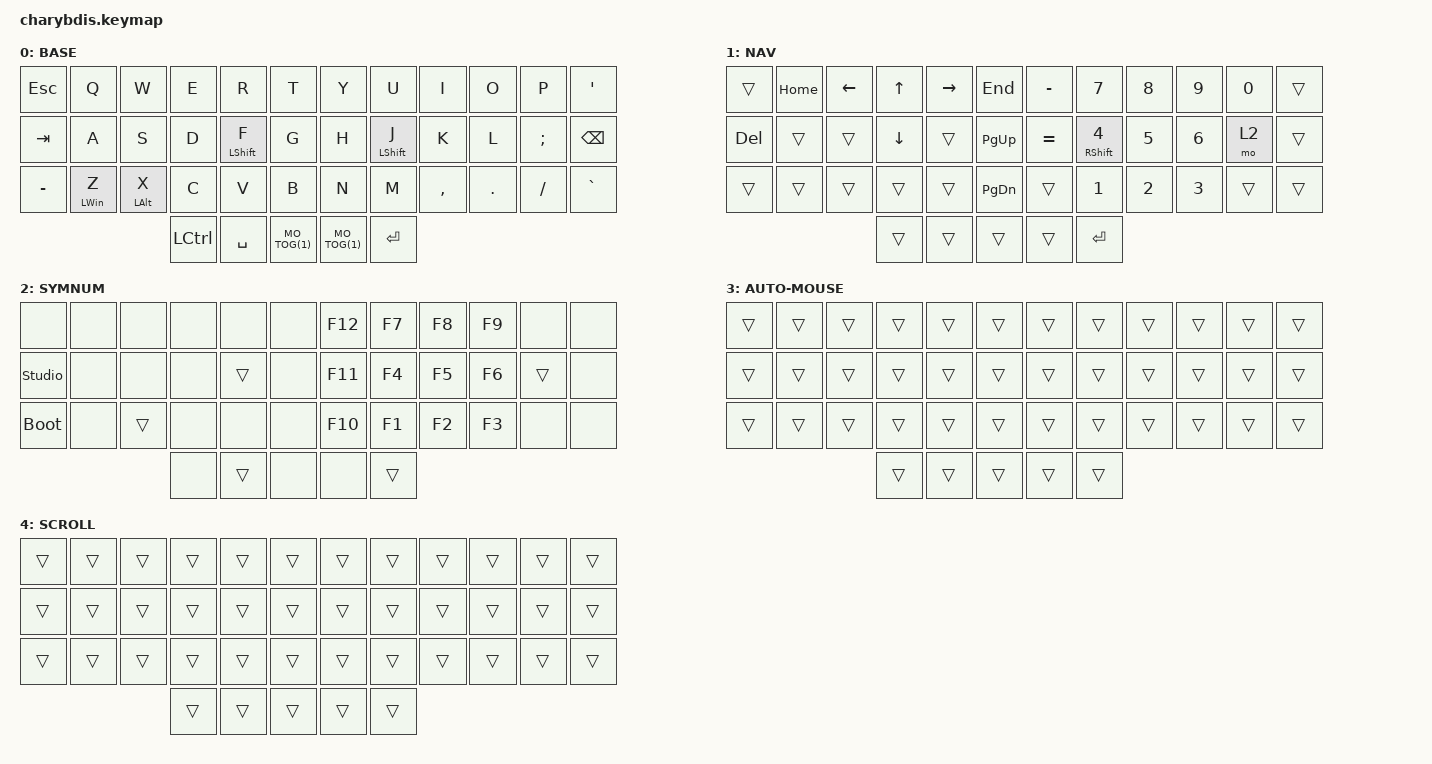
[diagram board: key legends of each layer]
#include <dt-bindings/zmk/mouse.h>
#include <input/processors.dtsi>
#include <dt-bindings/zmk/input_transform.h>
#include <behaviors.dtsi>
#include <dt-bindings/zmk/keys.h>
#include <dt-bindings/zmk/pointing.h>

#define U_TAPPING_TERM 200

#define MO_TOG(layer) &mo_tog layer layer   // Macro to apply momentary-layer-on-hold/toggle-layer-on-tap to a specific layer

/ {
    trackball_listener {
        compatible = "zmk,input-listener";
        device = <&trackball>;
        input-processors = <&zip_xy_scaler 1 2>, <&zip_temp_layer 3 400>;

        // Switch to auto-mouse temp layer, decrease sensitivity

        scroll {
            layers = <4>; // SCROLL
            input-processors =
                <&zip_xy_scaler 1 4>,
                <&zip_xy_to_scroll_mapper>,
                <&zip_scroll_transform (INPUT_TRANSFORM_Y_INVERT)>;
        };
    };

    combos {
        compatible = "zmk,combos";

        LeftClickRight {
            bindings = <&mkp LCLK>;
            key-positions = <19 20>;
        };

        RightClickRight {
            bindings = <&mkp RCLK>;
            key-positions = <20 21>;
        };

        MiddleClickRight {
            bindings = <&mkp MCLK>;
            key-positions = <21 22>;
        };

        ParaLeft {
            bindings = <&kp LEFT_PARENTHESIS>;
            key-positions = <4 16>;
        };

        ParaRight {
            bindings = <&kp RIGHT_PARENTHESIS>;
            key-positions = <7 19>;
        };

        BrakLeft {
            bindings = <&kp LEFT_BRACKET>;
            key-positions = <3 15>;
        };

        BrakRight {
            bindings = <&kp RIGHT_BRACKET>;
            key-positions = <8 20>;
        };

        BraceLeft {
            bindings = <&kp LEFT_BRACE>;
            key-positions = <2 14>;
        };

        BraceRight {
            bindings = <&kp RIGHT_BRACE>;
            key-positions = <9 21>;
        };

//        Delete {
//            bindings = <&kp DELETE>;
//            key-positions = <8 9>;
//        };

        CapsWord {
            bindings = <&caps_word>;
            key-positions = <17 18>;
        };

        ScrollSpeed {
            bindings = <&mo 4>;
            key-positions = <19 22>;
        };
    };

    behaviors {
        u_mt: u_mt {
            compatible = "zmk,behavior-hold-tap";
            label = "u_mt";
            #binding-cells = <2>;
            tapping_term_ms = <U_TAPPING_TERM>;
            flavor = "tap-preferred";
            bindings = <&kp>, <&kp>;
        };

        u_lt: u_lt {
            compatible = "zmk,behavior-hold-tap";
            label = "u_lt";
            #binding-cells = <2>;
            tapping_term_ms = <U_TAPPING_TERM>;
            flavor = "tap-preferred";
            bindings = <&mo>, <&kp>;
        };

        Shift_Enter: Shift_Enter {
            compatible = "zmk,behavior-hold-tap";
            label = "SHIFT_ENTER";
            bindings = <&kp>, <&kp>;

            #binding-cells = <2>;
            hold-trigger-key-positions = <40>;
            tapping-term-ms = <100>;
        };

        mo_tog: behavior_mo_tog {
            compatible = "zmk,behavior-hold-tap";
            #binding-cells = <2>;
            flavor = "hold-preferred";
            tapping-term-ms = <200>;
            bindings = <&mo>, <&tog>;
        };
    };

    // update &mo's to "MO_TOG(1)" in final version

    keymap {
        compatible = "zmk,keymap";

        BASE {
            bindings = <
&kp ESC    &kp Q             &kp W             &kp E      &kp R               &kp T         &kp Y      &kp U               &kp I      &kp O    &kp P          &kp SQT
&kp TAB    &kp A             &kp S             &kp D      &u_mt LEFT_SHIFT F  &kp G         &kp H      &u_mt LEFT_SHIFT J  &kp K      &kp L    &kp SEMICOLON  &kp BACKSPACE
&kp MINUS  &u_mt LEFT_WIN Z  &u_mt LEFT_ALT X  &kp C      &kp V               &kp B         &kp N      &kp M               &kp COMMA  &kp DOT  &kp FSLH       &kp GRAVE
                                               &kp LCTRL  &kp SPACE           MO_TOG(1)     MO_TOG(1)  &kp RET
            >;
        };

        NAV {
            bindings = <
&trans      &kp HOME   &kp LEFT   &kp UP_ARROW   &kp RIGHT     &kp END               &kp MINUS    &kp N7                      &kp N8        &kp N9        &kp N0  &trans
&kp DELETE  &trans     &trans     &kp DOWN       &trans        &kp PAGE_UP           &kp EQUAL    &u_mt RIGHT_SHIFT NUMBER_4  &kp N5        &kp NUMBER_6  &mo 2   &trans
&trans      &trans     &trans     &trans         &trans        &kp PAGE_DOWN         &trans       &kp NUMBER_1                &kp NUMBER_2  &kp NUMBER_3  &trans  &trans
                                  &trans         &trans        &trans                &trans       &kp RET
            >;
        };

        SYMNUM {
            bindings = <
&none           &none  &none   &none  &none   &none    &kp F12  &kp F7  &kp F8  &kp F9  &none   &none
&studio_unlock  &none  &none   &none  &trans  &none    &kp F11  &kp F4  &kp F5  &kp F6  &trans  &none
&bootloader     &none  &trans  &none  &none   &none    &kp F10  &kp F1  &kp F2  &kp F3  &none   &none
                               &none  &trans  &none    &none    &trans
            >;
        };

        AUTO-MOUSE {
            bindings = <
&trans  &trans  &trans  &trans     &trans  &trans       &trans  &trans  &trans  &trans  &trans  &trans
&trans  &trans  &trans  &trans     &trans  &trans       &trans  &trans  &trans  &trans  &trans  &trans
&trans  &trans  &trans  &trans     &trans  &trans       &trans  &trans  &trans  &trans  &trans  &trans
                        &trans     &trans  &trans       &trans  &trans
            >;
        };

        SCROLL {
            bindings = <
&trans  &trans  &trans  &trans  &trans  &trans    &trans  &trans  &trans  &trans  &trans  &trans
&trans  &trans  &trans  &trans  &trans  &trans    &trans  &trans  &trans  &trans  &trans  &trans
&trans  &trans  &trans  &trans  &trans  &trans    &trans  &trans  &trans  &trans  &trans  &trans
                        &trans  &trans  &trans    &trans  &trans
            >;
        };
    };
};
